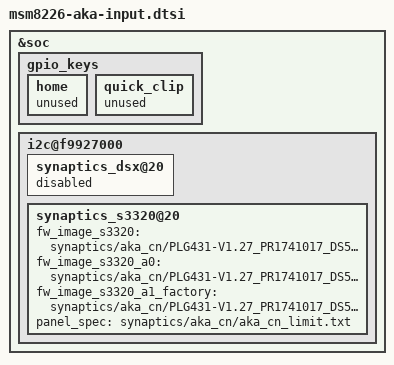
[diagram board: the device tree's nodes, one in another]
/* Copyright (c) 2013, LGE Electronics. All rights reserved.
 *
 * This program is free software; you can redistribute it and/or modify
 * it under the terms of the GNU General Public License version 2 and
 * only version 2 as published by the Free Software Foundation.
 *
 * This program is distributed in the hope that it will be useful,
 * but WITHOUT ANY WARRANTY; without even the implied warranty of
 * MERCHANTABILITY or FITNESS FOR A PARTICULAR PURPOSE.  See the
 * GNU General Public License for more details.
 */

&soc {
	gpio_keys {
		home {
			unused;
		};

		quick_clip {
			unused;
		};
	};

	i2c@f9927000 { /* BLSP1 QUP5 */
	    synaptics_dsx@20  {
			status = "disable";
		};

		synaptics_s3320@20 {
			status = "ok";
				fw_image_s3320 =            "synaptics/aka_cn/PLG431-V1.27_PR1741017_DS5.2.12.1013_4005019B.img";
				fw_image_s3320_a0 =         "synaptics/aka_cn/PLG431-V1.27_PR1741017_DS5.2.12.1013_4005019B.img";
				fw_image_s3320_a1_factory = "synaptics/aka_cn/PLG431-V1.27_PR1741017_DS5.2.12.1013_4005019B.img";
				panel_spec = "synaptics/aka_cn/aka_cn_limit.txt";
		};

	};

};
